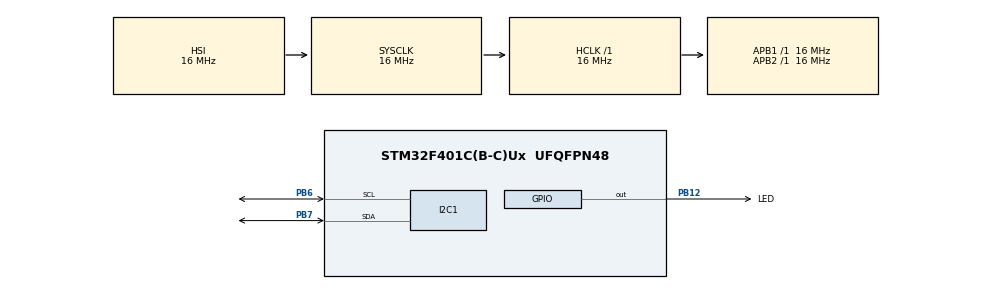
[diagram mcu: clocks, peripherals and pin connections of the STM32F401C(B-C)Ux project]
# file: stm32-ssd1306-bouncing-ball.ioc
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I2C1.I2C_Mode=I2C_Fast
Mcu.Family=STM32F4
Mcu.Name=STM32F401C(B-C)Ux
Mcu.Package=UFQFPN48
NVIC.PriorityGroup=NVIC_PRIORITYGROUP_4
PB12.GPIO_Label=LED
PB12.Signal=GPIO_Output
PB6.Mode=I2C
PB6.Signal=I2C1_SCL
PB7.Mode=I2C
PB7.Signal=I2C1_SDA
ProjectManager.HeapSize=0x200
ProjectManager.StackSize=0x400
ProjectManager.TargetToolchain=STM32CubeIDE
RCC.AHBFreq_Value=16000000
RCC.APB1Freq_Value=16000000
RCC.APB2Freq_Value=16000000
RCC.CortexFreq_Value=16000000
RCC.HSE_VALUE=25000000
RCC.HSI_VALUE=16000000
RCC.LSE_VALUE=32768
RCC.SYSCLKFreq_VALUE=16000000
RCC.VCOOutputFreq_Value=192000000
board=custom

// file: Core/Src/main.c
/* USER CODE BEGIN Header */
/**
 ******************************************************************************
 * @file           : main.c
 * @brief          : Main program body
 ******************************************************************************
 * @attention
 *
 * Copyright (c) 2026 STMicroelectronics.
 * All rights reserved.
 *
 * This software is licensed under terms that can be found in the LICENSE file
 * in the root directory of this software component.
 * If no LICENSE file comes with this software, it is provided AS-IS.
 *
 ******************************************************************************
 */
/* USER CODE END Header */
#include "main.h"

/* USER CODE BEGIN Includes */
#include <stdbool.h>
#include <stdio.h>
#include "ssd1306.h"
#include "ssd1306_fonts.h"
/* USER CODE END Includes */

I2C_HandleTypeDef hi2c1;

/* USER CODE BEGIN PV */
#define SCREEN_WIDTH 128
#define SCREEN_HEIGHT 64

float ball_x = SCREEN_WIDTH / 2.0f;
float ball_y = SCREEN_HEIGHT / 2.0f;

const int ball_size = 8; // 8x8 px

// Швидкість м'яча (зміщення в пікселях за один кадр)
// Можна змінювати ці значення, щоб зробити рух швидшим чи повільнішим
float ball_dx = 2.6f;
float ball_dy = 2.2f;

/* USER CODE END PV */

void SystemClock_Config(void);
static void MX_GPIO_Init(void);
static void MX_I2C1_Init(void);

int main(void)
{

  /* MCU Configuration--------------------------------------------------------*/

  /* Reset of all peripherals, Initializes the Flash interface and the Systick. */
  HAL_Init();

  /* Configure the system clock */
  SystemClock_Config();

  /* Initialize all configured peripherals */
  MX_GPIO_Init();
  MX_I2C1_Init();

  /* Infinite loop */
  /* USER CODE BEGIN WHILE */

  ssd1306_Init();

  bool rebound = false;
  bool led_on = false;
  uint32_t last_led_rebound_time = 0;

  uint32_t now = HAL_GetTick();
  uint32_t fps_timer = now;
  uint32_t frame_count = 0;
  uint32_t actual_fps = 0;
  char fps_string[8]; // Буфер для переведення числа в текст

  while (1) {
    now = HAL_GetTick();
    frame_count++;

    if (HAL_GetTick() - fps_timer >= 1000) {
        actual_fps = frame_count;
        frame_count = 0;
        fps_timer = HAL_GetTick();
    }

    ball_x += ball_dx;
    ball_y += ball_dy;
    rebound = false;

    // check LEFT and RIGHT borders
    if (ball_x <= 0) {
        ball_x = 0;
        ball_dx = -ball_dx; // horizontal rebound
        rebound = true;
    }  else if (ball_x >= SCREEN_WIDTH - ball_size) {
        ball_x = SCREEN_WIDTH - ball_size;
        ball_dx = -ball_dx;
        rebound = true;
    }

    // check TOP and BOTTOM borders
    if (ball_y <= 0) {
        ball_y = 0;
        ball_dy = -ball_dy; // vertical rebound
        rebound = true;
    }  else if (ball_y >= SCREEN_HEIGHT - ball_size) {
        ball_y = SCREEN_HEIGHT - ball_size;
        ball_dy = -ball_dy;
        rebound = true;
    }

    if (rebound && !led_on) {
      last_led_rebound_time = now;
      HAL_GPIO_WritePin(LED_GPIO_Port, LED_Pin, GPIO_PIN_SET);
      led_on = true;
    } else if (led_on && now - last_led_rebound_time > 100) {
      HAL_GPIO_WritePin(LED_GPIO_Port, LED_Pin, GPIO_PIN_RESET);
      led_on = false;
    }

    ssd1306_Fill(Black);
    ssd1306_FillRectangle((int)ball_x, (int)ball_y, (int)ball_x + ball_size, (int)ball_y + ball_size, White);

    sprintf(fps_string, "FPS:%lu", actual_fps);
    ssd1306_SetCursor(4, 4);
    ssd1306_WriteString(fps_string, Font_7x10, White);

    ssd1306_UpdateScreen();

    /* USER CODE END WHILE */

  }
}

void SystemClock_Config(void)
{
  RCC_OscInitTypeDef RCC_OscInitStruct = {0};
  RCC_ClkInitTypeDef RCC_ClkInitStruct = {0};

  /** Configure the main internal regulator output voltage
  */
  __HAL_RCC_PWR_CLK_ENABLE();
  __HAL_PWR_VOLTAGESCALING_CONFIG(PWR_REGULATOR_VOLTAGE_SCALE2);

  /** Initializes the RCC Oscillators according to the specified parameters
  * in the RCC_OscInitTypeDef structure.
  */
  RCC_OscInitStruct.OscillatorType = RCC_OSCILLATORTYPE_HSI;
  RCC_OscInitStruct.HSIState = RCC_HSI_ON;
  RCC_OscInitStruct.HSICalibrationValue = RCC_HSICALIBRATION_DEFAULT;
  RCC_OscInitStruct.PLL.PLLState = RCC_PLL_NONE;
  if (HAL_RCC_OscConfig(&RCC_OscInitStruct) != HAL_OK)
  {
    Error_Handler();
  }

  /** Initializes the CPU, AHB and APB buses clocks
  */
  RCC_ClkInitStruct.ClockType = RCC_CLOCKTYPE_HCLK|RCC_CLOCKTYPE_SYSCLK
                              |RCC_CLOCKTYPE_PCLK1|RCC_CLOCKTYPE_PCLK2;
  RCC_ClkInitStruct.SYSCLKSource = RCC_SYSCLKSOURCE_HSI;
  RCC_ClkInitStruct.AHBCLKDivider = RCC_SYSCLK_DIV1;
  RCC_ClkInitStruct.APB1CLKDivider = RCC_HCLK_DIV1;
  RCC_ClkInitStruct.APB2CLKDivider = RCC_HCLK_DIV1;

  if (HAL_RCC_ClockConfig(&RCC_ClkInitStruct, FLASH_LATENCY_0) != HAL_OK)
  {
    Error_Handler();
  }
}

static void MX_I2C1_Init(void)
{

  hi2c1.Instance = I2C1;
  hi2c1.Init.ClockSpeed = 400000;
  hi2c1.Init.DutyCycle = I2C_DUTYCYCLE_2;
  hi2c1.Init.OwnAddress1 = 0;
  hi2c1.Init.AddressingMode = I2C_ADDRESSINGMODE_7BIT;
  hi2c1.Init.DualAddressMode = I2C_DUALADDRESS_DISABLE;
  hi2c1.Init.OwnAddress2 = 0;
  hi2c1.Init.GeneralCallMode = I2C_GENERALCALL_DISABLE;
  hi2c1.Init.NoStretchMode = I2C_NOSTRETCH_DISABLE;
  if (HAL_I2C_Init(&hi2c1) != HAL_OK)
  {
    Error_Handler();
  }

}

static void MX_GPIO_Init(void)
{
  GPIO_InitTypeDef GPIO_InitStruct = {0};

  /* GPIO Ports Clock Enable */
  __HAL_RCC_GPIOB_CLK_ENABLE();

  /*Configure GPIO pin Output Level */
  HAL_GPIO_WritePin(LED_GPIO_Port, LED_Pin, GPIO_PIN_RESET);

  /*Configure GPIO pin : LED_Pin */
  GPIO_InitStruct.Pin = LED_Pin;
  GPIO_InitStruct.Mode = GPIO_MODE_OUTPUT_PP;
  GPIO_InitStruct.Pull = GPIO_NOPULL;
  GPIO_InitStruct.Speed = GPIO_SPEED_FREQ_LOW;
  HAL_GPIO_Init(LED_GPIO_Port, &GPIO_InitStruct);

}

void Error_Handler(void)
{
  __disable_irq();
  while (1) {
  }
}
#ifdef USE_FULL_ASSERT
/**
  * @brief  Reports the name of the source file and the source line number
  *         where the assert_param error has occurred.
  * @param  file: pointer to the source file name
  * @param  line: assert_param error line source number
  * @retval None
  */
void assert_failed(uint8_t *file, uint32_t line)
{
  /* USER CODE BEGIN 6 */
  /* User can add his own implementation to report the file name and line
     number, ex: printf("Wrong parameters value: file %s on line %d\r\n", file,
     line) */
  /* USER CODE END 6 */
}
#endif /* USE_FULL_ASSERT */
